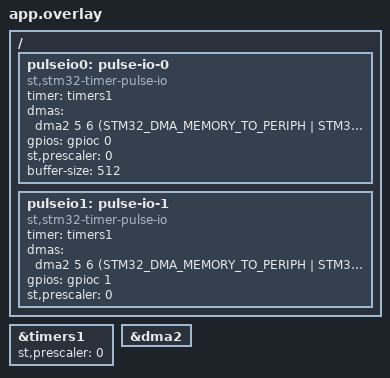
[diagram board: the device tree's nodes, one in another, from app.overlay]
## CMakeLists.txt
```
# SPDX-License-Identifier: Apache-2.0
cmake_minimum_required(VERSION 3.20.0)
find_package(Zephyr REQUIRED HINTS $ENV{ZEPHYR_BASE})
project(hq179)

# The Pulse IO driver under test is compiled from the copy named on the command
# line (-DHQ179_DRIVER_SRC=...), unpatched or patched; prj.conf keeps the
# in-tree copy out of the image.
if(NOT DEFINED HQ179_DRIVER_SRC)
  message(FATAL_ERROR "HQ179_DRIVER_SRC must name the copy of pulse_io_stm32_timer_dma.c to compile")
endif()

target_sources(app PRIVATE src/main.c src/sampler.c ${HQ179_DRIVER_SRC})
```

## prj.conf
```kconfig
CONFIG_PRINTK=y
CONFIG_BOOT_BANNER=n
CONFIG_SYS_CLOCK_TICKS_PER_SEC=10000
CONFIG_PULSE_IO=y
CONFIG_PULSE_IO_STM32_TIMER_DMA=n
CONFIG_DMA=y
CONFIG_GPIO=y
CONFIG_REBOOT=y
CONFIG_LOG=n
CONFIG_ASSERT=n
CONFIG_MAIN_STACK_SIZE=4096
```

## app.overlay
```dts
/* SPDX-License-Identifier: Apache-2.0 */
#include <zephyr/dt-bindings/dma/stm32_dma.h>

/ {
	/* Channel under test: TIM1 update -> DMA2 stream 5 channel 6 -> GPIOC BSRR, PC0. */
	pulseio0: pulse-io-0 {
		compatible = "st,stm32-timer-pulse-io";
		#pulse-io-cells = <1>;
		timer = <&timers1>;
		dmas = <&dma2 5 6
			(STM32_DMA_MEMORY_TO_PERIPH |
			 STM32_DMA_MEM_INC |
			 STM32_DMA_PERIPH_32BITS |
			 STM32_DMA_MEM_32BITS |
			 STM32_DMA_PRIORITY_HIGH)
			0>;
		dma-names = "tx";
		gpios = <&gpioc 0 GPIO_ACTIVE_HIGH>;
		st,prescaler = <0>;
		buffer-size = <512>;
		status = "okay";
	};

	/* Same timer and stream, PC1, no buffer-size: what the binding's default
	 * gives the driver. Never used while pulse-io-0 is busy. */
	pulseio1: pulse-io-1 {
		compatible = "st,stm32-timer-pulse-io";
		#pulse-io-cells = <1>;
		timer = <&timers1>;
		dmas = <&dma2 5 6
			(STM32_DMA_MEMORY_TO_PERIPH |
			 STM32_DMA_MEM_INC |
			 STM32_DMA_PERIPH_32BITS |
			 STM32_DMA_MEM_32BITS |
			 STM32_DMA_PRIORITY_HIGH)
			0>;
		dma-names = "tx";
		gpios = <&gpioc 1 GPIO_ACTIVE_HIGH>;
		st,prescaler = <0>;
		status = "okay";
	};
};

&timers1 {
	st,prescaler = <0>;
	status = "okay";
};

&dma2 {
	status = "okay";
};
```

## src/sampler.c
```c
/*
 * Copyright (c) 2026 the hq179 job
 *
 * SPDX-License-Identifier: Apache-2.0
 */

/*
 * The measurement path: TIM8 CC4 -> DMA2 stream 7 -> GPIOC_IDR into RAM, with a
 * TIM3 PWM of known period and duty on PC6 inside every window as its control.
 *
 * TIM8 has no devicetree node on the F446 under Zephyr and TIM3 none that is
 * enabled, so both are driven through their registers here; stream 7 of DMA2 is
 * claimed the same way. The measurement must yield to the product: the sampling
 * stream is programmed at the lowest priority level and is the higher-numbered
 * of the two, so the driver's stream 5 wins every arbitration tie. The image
 * reads both priority fields back and the gate asserts them.
 *
 * The stream raises no interrupt (no enable bit is set in its control register
 * and the FIFO error interrupt stays off), so Zephyr's DMA driver never sees an
 * interrupt for a stream it did not configure and cannot clear the flags this
 * window is judged by. The flags still latch in DMA2_HISR, and the image reads
 * them once the window must be over: while it is being sampled the processor
 * waits asleep and makes no bus access of its own (hq179_sampler_wait).
 */

#include <zephyr/kernel.h>
#include <zephyr/sys/util.h>

#include <soc.h>

#include "sampler.h"

/* RCC peripheral clock enables (RM0390 6.3). GPIOC and DMA2 are enabled by
 * Zephyr's own drivers as well; writing them again is idempotent and says what
 * this file depends on. TIM3 and TIM8 have no enabled devicetree node, so
 * nothing else turns them on.
 */
#define HQ_AHB1_GPIOC BIT(2)
#define HQ_AHB1_DMA2  BIT(22)
#define HQ_APB1_TIM3  BIT(1)
#define HQ_APB2_TIM8  BIT(1)

/* Timer bits (RM0390 17.4, 18.4). */
#define HQ_TIM_CR1_CEN   BIT(0)
#define HQ_TIM_EGR_UG    BIT(0)
#define HQ_TIM_CCER_CC1E BIT(0)
#define HQ_TIM_DIER_CC4DE BIT(12)
/* PWM mode 1 on channel 1 (OC1M = 110) with its preload enabled (OC1PE). */
#define HQ_TIM_CCMR1_PWM1 ((6u << 4) | BIT(3))
/* MMS = 001: the timer's counter-enable signal is what its trigger output
 * carries. Nothing else of CR2 is used by either timer here.
 */
#define HQ_TIM_CR2_MMS_ENABLE (1u << 4)
/* SMS = 110 (trigger mode) with TS = 000 (internal trigger 0, which is TIM1 for
 * TIM8 in RM0390's internal trigger connection table): a rising edge of that
 * trigger starts the counter and only starts it. The counter is not
 * reinitialised, by that edge or by any later one, and it keeps its own clock,
 * so one window is sampled on one uninterrupted cadence.
 */
#define HQ_TIM_SMCR_TRIGGER_ITR0 6u

/* DMA stream bits (RM0390 9.5). Peripheral to memory, 16-bit both sides,
 * memory incrementing, channel 7 (TIM8_CH4/TRIG/COM on stream 7), priority
 * level 0 (the lowest), no interrupt enable of any kind.
 */
#define HQ_DMA_CR_EN      BIT(0)
#define HQ_DMA_CR_MINC    BIT(10)
#define HQ_DMA_CR_PSIZE16 (1u << 11)
#define HQ_DMA_CR_MSIZE16 (1u << 13)
#define HQ_DMA_CR_CHSEL7  (7u << 25)
#define HQ_DMA_CR_PL_SHIFT 16u
#define HQ_SAMPLER_CR \
	(HQ_DMA_CR_CHSEL7 | HQ_DMA_CR_MSIZE16 | HQ_DMA_CR_PSIZE16 | HQ_DMA_CR_MINC)

/* The five per-stream flags of DMA2_HISR, and where stream 7's group starts. */
#define HQ_DMA_FLAGS       0x3Du
#define HQ_DMA_TCIF        0x20u
#define HQ_STREAM7_SHIFT   22u
/* The window's own length in timer clocks, and the clocks per microsecond of
 * the 96 MHz the image prints as sysclk.
 */
#define HQ_WINDOW_CLOCKS (HQ179_SAMPLES * HQ179_SAMPLE_CLOCKS)
#define HQ_CLOCKS_PER_US 96u
/* Added to the sleep that waits a window out: one kernel tick of 100 us, which
 * a sleep of a given length may round up by, and the time between the window's
 * origin and its first sample - the transmit's own setup, 512 encoded words and
 * one DMA configuration, before the frame starts the sampling counter. A sleep
 * that still ends early only costs another one in the loop below.
 */
#define HQ_SLEEP_SLACK_US 300u
/* Three window lengths: long enough that a completed transfer is never missed,
 * short enough that a stream which never completes does not stall the image.
 */
#define HQ_WAIT_CLOCKS (3u * HQ_WINDOW_CLOCKS)

static uint16_t samples[HQ179_SAMPLES];
static uint32_t window_t0;

static uint32_t field(uint32_t value, uint32_t pin, uint32_t width)
{
	return (value >> (width * pin)) & ((1u << width) - 1u);
}

static void set_field(volatile uint32_t *reg, uint32_t pin, uint32_t width, uint32_t value)
{
	uint32_t mask = ((1u << width) - 1u) << (width * pin);

	*reg = (*reg & ~mask) | ((value << (width * pin)) & mask);
}

static uint32_t sample_bit(uint32_t index, uint32_t bit)
{
	return (uint32_t)(samples[index] >> bit) & 1u;
}

void hq179_spin(uint32_t clocks)
{
	uint32_t start = k_cycle_get_32();

	while (k_cycle_get_32() - start < clocks) {
	}
}

uint32_t hq179_idr_bit(uint32_t bit)
{
	return (GPIOC->IDR >> bit) & 1u;
}

void hq179_drive(uint32_t pin, uint32_t level)
{
	GPIOC->BSRR = level != 0u ? BIT(pin) : BIT(pin) << 16;
}

uint32_t hq179_moder(uint32_t pin)
{
	return field(GPIOC->MODER, pin, 2u);
}

uint32_t hq179_ospeedr(uint32_t pin)
{
	return field(GPIOC->OSPEEDR, pin, 2u);
}

/* Tie the sampling grid to the frame: the driver's counter-enable signal starts
 * the sampling counter.
 *
 * One sample every 8 clocks measures a pulse of 12 or 13 clocks as one or two
 * samples, depending only on where the pulse falls between two samples, so the
 * mean over the 20 repetitions resolves below one sample only while that phase
 * moves from repetition to repetition.
 *
 * Two earlier versions of this image moved the phase before the frame started -
 * the first in the sampling counter, the second in the compare value plus a
 * wait on the sampling counter - and both measured every run of a frame as the
 * same number of samples in all 20 repetitions of both reset phases, which is
 * what a grid that never moves relative to the frame does. Anything that ties
 * the processor's timing to the sampling stream between such a shift and the
 * frame takes the shift back: the stream writes its samples into the same SRAM
 * that the driver's encoder writes its 512 words into, and a loop that is held
 * up by one clock whenever the two coincide settles at a fixed position in the
 * grid and carries the frame start with it.
 *
 * So the phase is taken from the driver's own timer, after any such loop has
 * run. TIM1's trigger output carries its counter-enable signal and that trigger
 * starts TIM8, from the count of 0 that arming leaves it at, so a frame begins
 * at count 0 of the sampling counter and the window's first sample falls CCR4
 * clocks later, which is where hq179_sampler_arm() puts this repetition's phase.
 *
 * The trigger starts the counter and never reinitialises it, and that is what
 * keeps every sample of a window exactly 8 clocks from the one before it. A
 * counter the trigger reinitialises - reset mode, which an earlier version of
 * this image used - moves the grid's phase in the middle of the window instead,
 * and the single interval across that step is shorter than 8 clocks whenever
 * the new phase precedes the old one. A short interval fits one more sample
 * into whichever run of the control PWM it falls in, and that is a sample the
 * control cannot have: 40 clocks of high time hold five samples of an 8-clock
 * grid, and a sixth only because a sample may be read late. Two bench runs of
 * these images reported 7 samples of high time and 17 of low that way, which is
 * the measurement and not the driver. Starting the counter leaves the step
 * before the first sample of the window, where there is nothing measured yet.
 *
 * Writing MMS selects what the driver's timer puts on its trigger output and
 * nothing else: no count, no update event, no DMA request and nothing on the
 * pin changes, and the driver itself never writes CR2 (the reference copy of
 * the driver under reference/hq179/ writes CR1, PSC, ARR, RCR, DIER and EGR).
 */
static void grid_trigger(void)
{
	TIM1->CR2 = HQ_TIM_CR2_MMS_ENABLE;
	TIM8->SMCR = HQ_TIM_SMCR_TRIGGER_ITR0;
}

void hq179_grid_trigger_regs(uint32_t *driver_cr2, uint32_t *sampler_smcr)
{
	*driver_cr2 = TIM1->CR2;
	*sampler_smcr = TIM8->SMCR;
}

void hq179_sampler_setup(void)
{
	RCC->AHB1ENR |= HQ_AHB1_GPIOC | HQ_AHB1_DMA2;
	RCC->APB1ENR |= HQ_APB1_TIM3;
	RCC->APB2ENR |= HQ_APB2_TIM8;
	(void)RCC->APB2ENR; /* the write must have reached the bus before the first access */

	/* The pads: PC6 carries TIM3_CH1 (alternate function 2), and all three
	 * pins get the fast slew rate. How fast a pad rises is the integrator's
	 * setting, not the driver's, so it is set here and printed.
	 */
	set_field(&GPIOC->AFR[0], HQ179_BIT_PC6, 4u, 2u);
	set_field(&GPIOC->MODER, HQ179_BIT_PC6, 2u, 2u);
	set_field(&GPIOC->OSPEEDR, HQ179_BIT_PC0, 2u, 2u);
	set_field(&GPIOC->OSPEEDR, HQ179_BIT_PC1, 2u, 2u);
	set_field(&GPIOC->OSPEEDR, HQ179_BIT_PC6, 2u, 2u);

	/* The control, running from here until the done line: 159 clocks per
	 * period with 40 high, read back from these registers by the gate.
	 */
	TIM3->CR1 = 0u;
	TIM3->PSC = 0u;
	TIM3->ARR = HQ179_PWM_ARR;
	TIM3->CCR1 = HQ179_PWM_CCR;
	TIM3->CCMR1 = HQ_TIM_CCMR1_PWM1;
	TIM3->CCER = HQ_TIM_CCER_CC1E;
	TIM3->EGR = HQ_TIM_EGR_UG;
	TIM3->SR = 0u;
	TIM3->CR1 = HQ_TIM_CR1_CEN;

	/* Set here as well as in every window, so the start can print the two
	 * registers the grid's phase rests on.
	 */
	grid_trigger();
}

void hq179_sampler_arm(uint32_t rep)
{
	/* A pattern no port read can produce for these three pins, so a sample
	 * the stream never wrote cannot pass for one it did.
	 */
	for (uint32_t index = 0u; index < HQ179_SAMPLES; index++) {
		samples[index] = 0xFFFFu;
	}

	DMA2_Stream7->CR = 0u;
	while ((DMA2_Stream7->CR & HQ_DMA_CR_EN) != 0u) {
	}
	DMA2->HIFCR = HQ_DMA_FLAGS << HQ_STREAM7_SHIFT;
	DMA2_Stream7->PAR = (uint32_t)(uintptr_t)&GPIOC->IDR;
	DMA2_Stream7->M0AR = (uint32_t)(uintptr_t)samples;
	DMA2_Stream7->NDTR = HQ179_SAMPLES;
	DMA2_Stream7->FCR = 0u; /* direct mode: no FIFO, no FIFO error interrupt */
	DMA2_Stream7->CR = HQ_SAMPLER_CR;
	DMA2_Stream7->CR |= HQ_DMA_CR_EN;

	/* One CC4 event every HQ179_SAMPLE_CLOCKS clocks, the first of them CCR4
	 * clocks after the counter starts, which grid_trigger() above has the
	 * driver's counter enable do at the start of a frame. So CCR4 is this
	 * repetition's phase of the grid: seven values for eight phases, three
	 * repetitions each and two for the seventh, which holds the quantisation
	 * left in the mean of 20 repetitions under 1.5 clocks. It stays between 1
	 * and ARR: 0 would leave it to the silicon whether a match at the
	 * counter's reload is an event at all, and a value above ARR would be no
	 * event ever. CR2 keeps CCDS at 0, so the request follows the compare
	 * event and not the update event.
	 */
	TIM8->CR1 = 0u;
	TIM8->DIER = 0u;
	TIM8->CR2 = 0u;
	TIM8->PSC = 0u;
	TIM8->ARR = HQ179_SAMPLE_CLOCKS - 1u;
	TIM8->CCR4 = 1u + rep % (HQ179_SAMPLE_CLOCKS - 1u);
	TIM8->CCMR2 = 0u; /* channel 4 an output, compare mode frozen */
	TIM8->CCER = 0u;  /* the pin is not driven; only the compare event is wanted */
	/* The trigger again in every window: the driver reconfigures its timer
	 * before each one, and this image does not depend on what that leaves
	 * in the two registers the grid's phase rests on.
	 */
	grid_trigger();
	/* Reloads the prescaler and leaves the counter at 0, so the first sample
	 * of the window falls CCR4 clocks after the trigger starts it. The
	 * counter is left stopped here: CR1 above cleared its enable, and a
	 * trigger edge from a transfer that runs between two windows can start it
	 * again, which is why arming clears it rather than assuming it.
	 */
	TIM8->EGR = HQ_TIM_EGR_UG;
	TIM8->SR = 0u;
	TIM8->DIER = HQ_TIM_DIER_CC4DE;
}

void hq179_sampler_start(void)
{
	/* The window's time origin, taken before the call under test. The
	 * sampling counter is not enabled here: the driver's own counter enable
	 * starts it at the frame's start (grid_trigger above), and
	 * hq179_sampler_wait() starts it for a window no frame ever began in.
	 */
	window_t0 = k_cycle_get_32();
}

uint32_t hq179_elapsed(void)
{
	return k_cycle_get_32() - window_t0;
}

void hq179_sampler_priorities(uint32_t *driver_pl, uint32_t *sampler_pl)
{
	*driver_pl = (DMA2_Stream5->CR >> HQ_DMA_CR_PL_SHIFT) & 3u;
	*sampler_pl = (DMA2_Stream7->CR >> HQ_DMA_CR_PL_SHIFT) & 3u;
}

void hq179_sampler_wait(struct hq179_window *out)
{
	uint32_t flags;
	uint32_t elapsed = hq179_elapsed();
	uint32_t left = HQ_WINDOW_CLOCKS;

	/* A window no frame ever began in: no counter-enable edge came, so
	 * nothing started the sampling counter, and the grid starts here instead.
	 * The qualification case makes no transfer at all, and a request the
	 * driver refuses before it reaches its timer - the instance without a
	 * buffer-size, on the driver as the PR has it - never enables that
	 * counter either. Such a window records the resting level of the line and
	 * the control PWM, which is exactly what those two cases are read for.
	 *
	 * There is no frame for the grid to be tied to here, so the counter is
	 * taken out of slave mode before it is started: a counter started by
	 * software while a trigger may still set the same bit is one more thing
	 * to reason about, and the phase of a window with no frame in it is of no
	 * consequence. The cadence is the same 8 clocks either way.
	 */
	out->self_started = 0u;
	if ((TIM8->CR1 & HQ_TIM_CR1_CEN) == 0u) {
		TIM8->SMCR = 0u;
		TIM8->CR1 = HQ_TIM_CR1_CEN;
		out->self_started = 1u;
	} else {
		left = elapsed < HQ_WINDOW_CLOCKS ? HQ_WINDOW_CLOCKS - elapsed : 0u;
	}

	/* Wait the window out asleep, and only then read the stream.
	 *
	 * Nothing the processor does can make the window shorter: it is
	 * HQ_WINDOW_CLOCKS long by construction. A loop that polls the stream's
	 * flags or the system timer meanwhile puts a processor access between two
	 * samples every few clocks, and an access that outlasts the slack one
	 * sample leaves on the buses delays the next sample's read of the port. A
	 * sample read late crosses whatever edge fell in between and is counted in
	 * the next run instead of its own, which is a whole sample of error in a
	 * control whose 40-clock high time is five samples. The window has room for
	 * one such sample and no more, and that room belongs to the driver's own
	 * traffic, which a window must tolerate because it is the thing being
	 * measured.
	 *
	 * Asleep there is no such access: Zephyr's idle thread halts the core, and
	 * the only accesses left in a window are the driver's own and the interrupt
	 * its transfer completes in.
	 */
	if (left != 0u) {
		k_sleep(K_USEC(left / HQ_CLOCKS_PER_US + HQ_SLEEP_SLACK_US));
	}
	for (;;) {
		flags = (DMA2->HISR >> HQ_STREAM7_SHIFT) & HQ_DMA_FLAGS;
		if ((flags & HQ_DMA_TCIF) != 0u) {
			break;
		}
		if (hq179_elapsed() >= HQ_WAIT_CLOCKS) {
			break;
		}
		/* The window is over by now; a stream that has not finished is
		 * waited for in whole kernel ticks, asleep as well.
		 */
		k_msleep(1);
	}
	out->dur = hq179_elapsed();
	out->flags = (DMA2->HISR >> HQ_STREAM7_SHIFT) & HQ_DMA_FLAGS;
	out->ndtr = DMA2_Stream7->NDTR;

	TIM8->CR1 = 0u;
	TIM8->DIER = 0u;
	DMA2_Stream7->CR = 0u;
	while ((DMA2_Stream7->CR & HQ_DMA_CR_EN) != 0u) {
	}
}

void hq179_runs_of(uint32_t bit, struct hq179_runs *out)
{
	uint32_t level = sample_bit(0u, bit);
	uint32_t start = 0u;
	uint32_t closed = 0u; /* runs the window ended inside, so not the last one */

	for (uint32_t index = 0u; index < HQ179_RUNS_KEPT; index++) {
		out->inner[index] = 0u;
	}
	out->first = level;
	out->first_len = HQ179_SAMPLES;

	for (uint32_t index = 1u; index < HQ179_SAMPLES; index++) {
		uint32_t next = sample_bit(index, bit);

		if (next == level) {
			continue;
		}
		if (closed == 0u) {
			out->first_len = index - start;
		} else if (closed - 1u < HQ179_RUNS_KEPT) {
			/* Run number `closed`, which is an inner run unless the
			 * window ends in the next one; inner_count below drops it
			 * in that case.
			 */
			out->inner[closed - 1u] = index - start;
		}
		closed++;
		start = index;
		level = next;
	}

	out->nruns = closed + 1u;
	out->last = level;
	out->last_len = HQ179_SAMPLES - start;
	out->inner_count = out->nruns > 2u ? MIN(out->nruns - 2u, HQ179_RUNS_KEPT) : 0u;
}

void hq179_pwm_of(uint32_t bit, struct hq179_pwm *out)
{
	uint32_t level = sample_bit(0u, bit);
	uint32_t start = 0u;
	uint32_t previous_rise = 0u;

	out->edges = 0u;
	out->first = 0u;
	out->last = 0u;
	out->hi_min = UINT32_MAX;
	out->hi_max = 0u;
	out->lo_min = UINT32_MAX;
	out->lo_max = 0u;
	out->per_min = UINT32_MAX;
	out->per_max = 0u;

	for (uint32_t index = 1u; index < HQ179_SAMPLES; index++) {
		uint32_t next = sample_bit(index, bit);

		if (next == level) {
			continue;
		}
		if (start != 0u) {
			/* A run that both began and ended on an edge this window
			 * recorded. The partial run at each end of the window is
			 * not a measurement of the control's high or low time.
			 */
			uint32_t length = index - start;

			if (level != 0u) {
				out->hi_min = MIN(out->hi_min, length);
				out->hi_max = MAX(out->hi_max, length);
			} else {
				out->lo_min = MIN(out->lo_min, length);
				out->lo_max = MAX(out->lo_max, length);
			}
		}
		if (next != 0u) {
			out->edges++;
			if (out->edges == 1u) {
				out->first = index;
			} else {
				uint32_t period = index - previous_rise;

				out->per_min = MIN(out->per_min, period);
				out->per_max = MAX(out->per_max, period);
			}
			previous_rise = index;
			out->last = index;
		}
		start = index;
		level = next;
	}

	/* Nothing measured stays 0 rather than the sentinel, so the gate reports
	 * a control that did not run instead of an implausible length.
	 */
	if (out->hi_max == 0u) {
		out->hi_min = 0u;
	}
	if (out->lo_max == 0u) {
		out->lo_min = 0u;
	}
	if (out->per_max == 0u) {
		out->per_min = 0u;
	}
}
```

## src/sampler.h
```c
/*
 * Copyright (c) 2026 the hq179 job
 *
 * SPDX-License-Identifier: Apache-2.0
 */

/*
 * The in-chip measurement path of hq179, and nothing of the driver under test.
 *
 * Nothing is wired to the board. DMA2 stream 7 copies the 16-bit GPIOC input
 * data register into RAM on every TIM8 CC4 event, one sample every
 * HQ179_SAMPLE_CLOCKS timer clocks, for HQ179_SAMPLES samples. The driver
 * drives PC0 (and PC1 for the second instance) by writing the same port's BSRR,
 * and a TIM3 PWM of known period and duty comes out of PC6, so the control and
 * the pin under test lie in the very same samples.
 *
 * These functions only measure and reduce; every verdict is the gate's.
 */

#ifndef HQ179_SAMPLER_H_
#define HQ179_SAMPLER_H_

#include <stdint.h>

/* 20000 samples of 8 timer clocks are 160000 clocks (1.667 ms): the longest
 * frame of this job (512 ticks of 193 clocks = 98816) plus a tail of more than
 * 60000 clocks, so a frame always ends well inside the window. 8 clocks is
 * shorter than the shortest judged pulse (one tick of 12 clocks at 8 MHz).
 */
#define HQ179_SAMPLES       20000u
#define HQ179_SAMPLE_CLOCKS 8u
/* Inner run lengths kept per window; the run count itself is always complete.
 * The frames of this job show at most 23 runs between the resting levels.
 */
#define HQ179_RUNS_KEPT 64u
/* The control: TIM3 CH1 on PC6, 159 clocks per period (prime, so the 8-clock
 * samples sweep every phase of it) with 40 clocks high and 119 low.
 */
#define HQ179_PWM_ARR 158u
#define HQ179_PWM_CCR 40u

/* The bits of GPIOC the window is read for. */
#define HQ179_BIT_PC0 0u
#define HQ179_BIT_PC1 1u
#define HQ179_BIT_PC6 6u

/** What the sampling stream itself reported about one window. */
struct hq179_window {
	/* DMA2_HISR of stream 7, shifted down to bit 0 and masked to the five
	 * stream flags: transfer complete, half transfer, and the FIFO, direct
	 * mode and transfer errors.
	 */
	uint32_t flags;
	uint32_t ndtr; /* transfers left; 0 when the whole window was recorded */
	uint32_t dur;  /* timer clocks from the window's start to transfer complete */
	/* 0 when the frame's own counter enable started the sampling counter, 1
	 * when no frame did and the image started it itself. A framed window
	 * reporting 1 is a measurement that missed its frame, not a driver that
	 * put nothing on the line.
	 */
	uint32_t self_started;
};

/** One bit of the port, run-length encoded over the whole window. */
struct hq179_runs {
	uint32_t nruns;     /* every run, the two at the window's ends included */
	uint32_t first;     /* level of the run the window begins in */
	uint32_t first_len; /* its length in samples */
	uint32_t last;      /* level of the run the window ends in */
	uint32_t last_len;
	uint32_t inner_count; /* min(nruns - 2, HQ179_RUNS_KEPT) */
	uint32_t inner[HQ179_RUNS_KEPT];
};

/** The control PWM as the same samples show it; lengths in samples. */
struct hq179_pwm {
	uint32_t edges; /* rising edges: a low sample followed by a high one */
	uint32_t first; /* sample index of the first rising edge */
	uint32_t last;  /* sample index of the last rising edge */
	uint32_t hi_min;
	uint32_t hi_max;
	uint32_t lo_min;
	uint32_t lo_max;
	uint32_t per_min; /* rising edge to rising edge */
	uint32_t per_max;
};

/** Clocks, the control PWM on PC6 and the pad slew rates; once per start. */
void hq179_sampler_setup(void);

/** Point the stream at a fresh window and put the sampling grid at this
 *  repetition's phase (the compare value of the sampling timer, which is the
 *  grid's offset from the start of a frame; see sampler.c for why the phase
 *  must move from repetition to repetition and why it is tied to the frame).
 */
void hq179_sampler_arm(uint32_t rep);

/** Open the window: take its time origin, taken before the call under test.
 *  The sampling counter is started by the driver's own counter enable, at the
 *  start of the frame, and never reinitialised after that, so one window is one
 *  uninterrupted 8-clock cadence; a window no frame begins in is started by
 *  hq179_sampler_wait().
 */
void hq179_sampler_start(void);

/** The two registers the grid's phase rests on, read back: the trigger output
 *  of the driver's timer and the slave mode of the sampling timer.
 */
void hq179_grid_trigger_regs(uint32_t *driver_cr2, uint32_t *sampler_smcr);

/** Timer clocks since that origin. */
uint32_t hq179_elapsed(void);

/** The DMA2 priority level fields of the driver's stream 5 and the sampler's 7. */
void hq179_sampler_priorities(uint32_t *driver_pl, uint32_t *sampler_pl);

/** Wait for the window to complete - asleep, so the processor takes no bus
 *  access between two samples - then stop sampling. Starts the grid first if no
 *  frame did.
 */
void hq179_sampler_wait(struct hq179_window *out);

/** Reduce the recorded window: one bit, run-length encoded. */
void hq179_runs_of(uint32_t bit, struct hq179_runs *out);

/** Reduce the recorded window: the control PWM's runs and periods. */
void hq179_pwm_of(uint32_t bit, struct hq179_pwm *out);

/** One bit of GPIOC_IDR, read now. */
uint32_t hq179_idr_bit(uint32_t bit);

/** Drive one GPIOC pin through BSRR, as the driver does. */
void hq179_drive(uint32_t pin, uint32_t level);

/** The MODER and OSPEEDR fields of one GPIOC pin. */
uint32_t hq179_moder(uint32_t pin);
uint32_t hq179_ospeedr(uint32_t pin);

/** Busy-wait a number of timer clocks (short waits, no scheduling). */
void hq179_spin(uint32_t clocks);

#endif /* HQ179_SAMPLER_H_ */
```
